# PIC32MM0128GPM064 register map
Vendor: Microchip
Registers are 32-bit, read-write, reset 0x0 unless marked. A register's access mark holds for its fields unless they carry their own. Addresses are absolute, and some are shared; only a register's first bit layout is shown; [hi:lo] are bit positions; {n}, {i} and the like mark numbered series.

## INT
0x1F802A00 RPCON
  [11] IOLOCK
0x1F802A20 RPINR1
  [4:0] INT4R
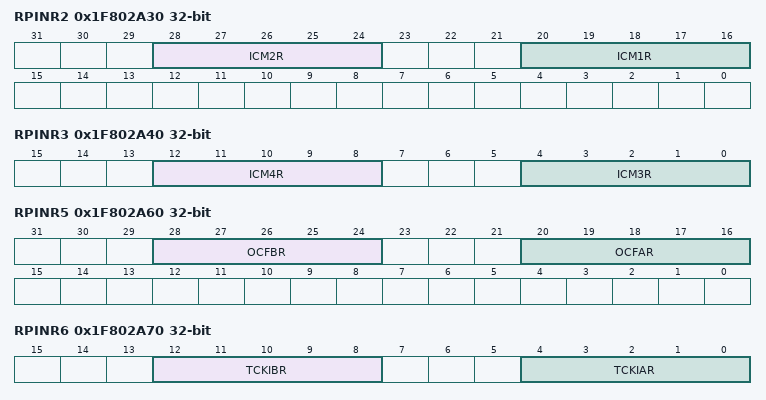
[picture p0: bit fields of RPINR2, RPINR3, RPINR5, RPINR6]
0x1F802A30 RPINR2
  [28:24] ICM2R, [20:16] ICM1R
0x1F802A40 RPINR3
  [12:8] ICM4R, [4:0] ICM3R
0x1F802A60 RPINR5
  [28:24] OCFBR, [20:16] OCFAR
0x1F802A70 RPINR6
  [12:8] TCKIBR, [4:0] TCKIAR
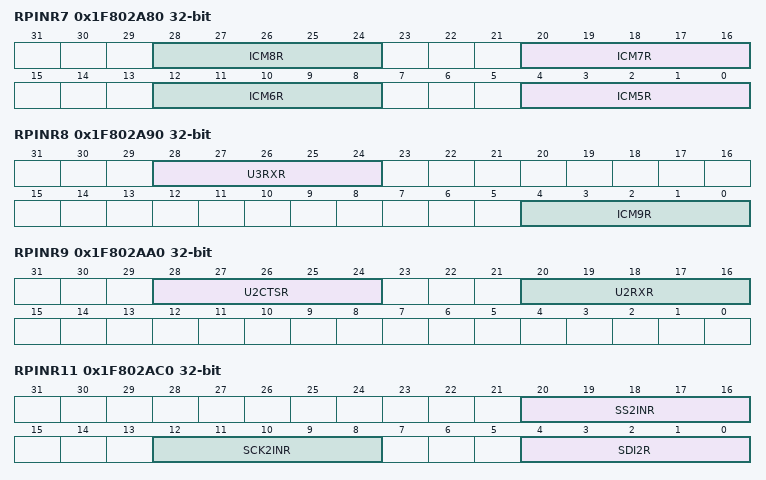
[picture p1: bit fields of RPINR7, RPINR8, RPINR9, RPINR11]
0x1F802A80 RPINR7
  [8n-36:8n-40] ICM{n}R (n=5..8)
0x1F802A90 RPINR8
  [28:24] U3RXR, [4:0] ICM9R
0x1F802AA0 RPINR9
  [28:24] U2CTSR, [20:16] U2RXR
0x1F802AB0 RPINR10
  [28:24] U3CTSR
0x1F802AC0 RPINR11
  [20:16] SS2INR, [12:8] SCK2INR, [4:0] SDI2R
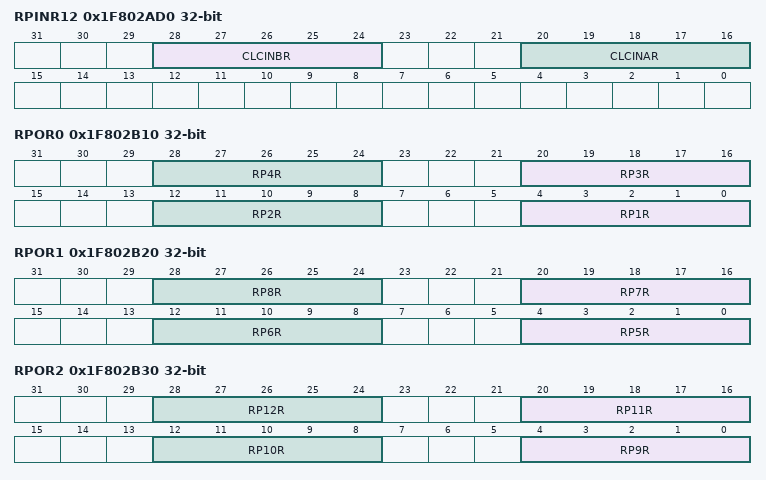
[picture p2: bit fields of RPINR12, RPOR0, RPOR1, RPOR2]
0x1F802AD0 RPINR12
  [28:24] CLCINBR, [20:16] CLCINAR
0x1F802B10 RPOR0
  [8n-4:8n-8] RP{n}R (n=1..4)
0x1F802B20 RPOR1
  [8n-36:8n-40] RP{n}R (n=5..8)
0x1F802B30 RPOR2
  [8n-68:8n-72] RP{n}R (n=9..12)
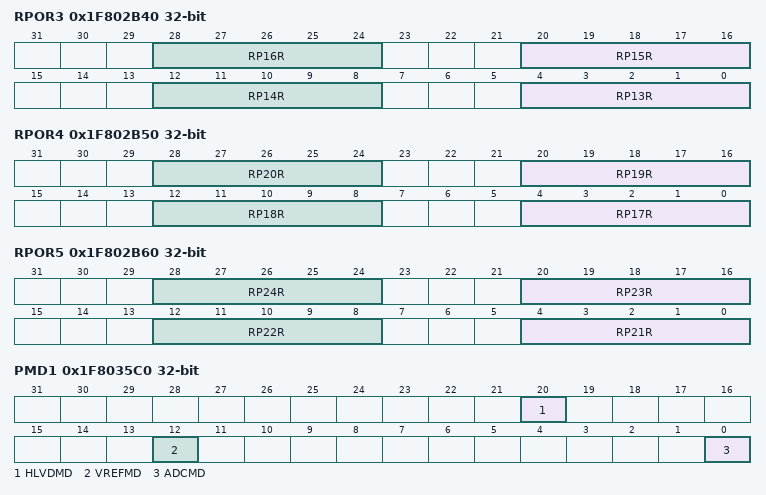
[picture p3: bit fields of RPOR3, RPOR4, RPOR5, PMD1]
0x1F802B40 RPOR3
  [8n-100:8n-104] RP{n}R (n=13..16)
0x1F802B50 RPOR4
  [8n-132:8n-136] RP{n}R (n=17..20)
0x1F802B60 RPOR5 reset not defined — (power-on value ---xxxxx---xxxxx---xxxxx---xxxxx)
  [8n-164:8n-168] RP{n}R (n=21..24)
0x1F8035B0 PMDCON
  [11] PMDLOCK
0x1F8035C0 PMD1
  [20] HLVDMD, [12] VREFMD, [0] ADCMD
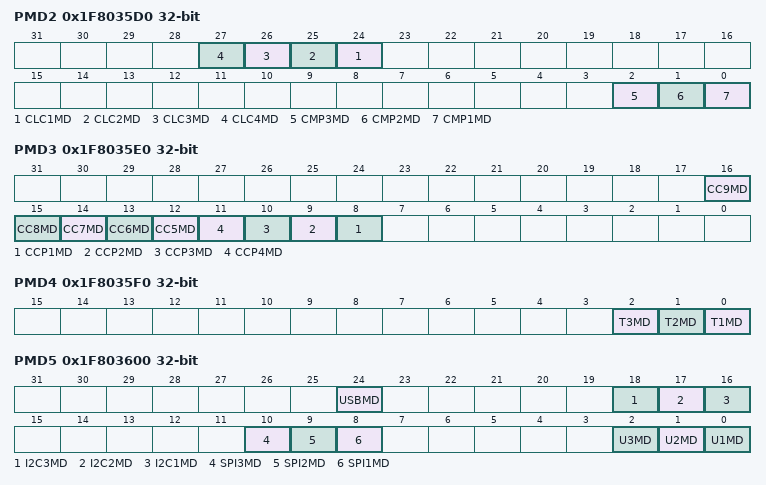
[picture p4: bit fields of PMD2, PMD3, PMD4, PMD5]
0x1F8035D0 PMD2
  [n+23] CLC{n}MD (n=1..4), [2] CMP3MD, [1] CMP2MD, [0] CMP1MD
0x1F8035E0 PMD3
  [n+7] CC{n}MD (n=5..9), [n+7] CCP{n}MD (n=1..4)
0x1F8035F0 PMD4
  [2] T3MD, [1] T2MD, [0] T1MD
0x1F803600 PMD5
  [24] USBMD, [18] I2C3MD, [17] I2C2MD, [16] I2C1MD, [10] SPI3MD, [9] SPI2MD, [8] SPI1MD, [2] U3MD, [1] U2MD, [0] U1MD
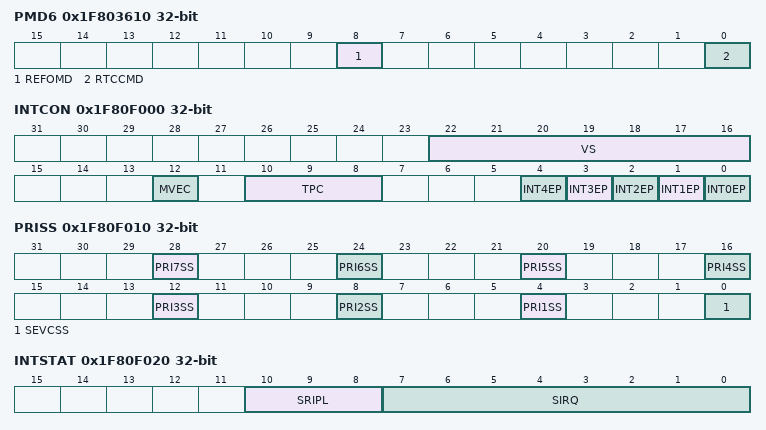
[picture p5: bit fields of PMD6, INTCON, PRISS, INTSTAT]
0x1F803610 PMD6
  [8] REFOMD, [0] RTCCMD
0x1F803620 PMD7
  [4] DMAMD
0x1F80F000 INTCON reset not defined — (power-on value ---------0000000-x-0-000---00000)
  [22:16] VS, [12] MVEC, [10:8] TPC, [n] INT{n}EP (n=0..4)
0x1F80F010 PRISS reset not defined — (power-on value ---x---x---x---x---x---x---x---x)
  [4n] PRI{n}SS (n=1..7), [0] SEVCSS
0x1F80F020 INTSTAT ro
  [10:8] SRIPL, [7:0] SIRQ
0x1F80F030 IPTMR
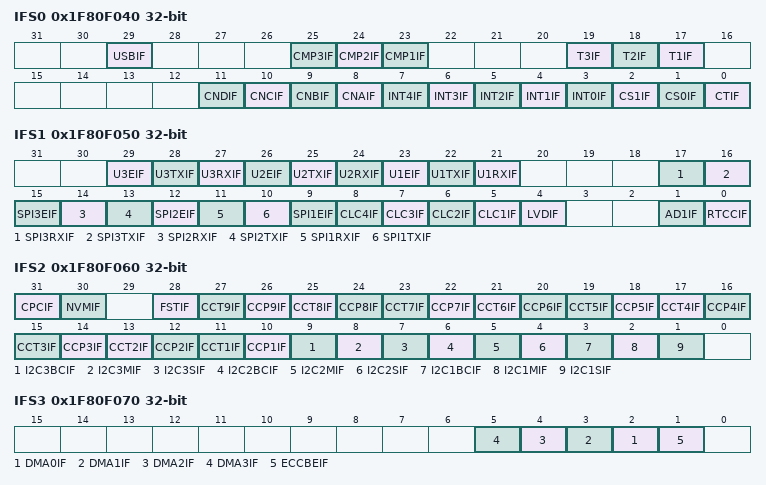
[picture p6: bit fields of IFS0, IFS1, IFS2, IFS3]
0x1F80F040 IFS0
  [29] USBIF, [25] CMP3IF, [24] CMP2IF, [23] CMP1IF, [19] T3IF, [18] T2IF, [17] T1IF, [11] CNDIF, [10] CNCIF, [9] CNBIF, [8] CNAIF, [n+3] INT{n}IF (n=0..4), [2] CS1IF, [1] CS0IF, [0] CTIF
0x1F80F050 IFS1
  [29] U3EIF, [28] U3TXIF, [27] U3RXIF, [26] U2EIF, [25] U2TXIF, [24] U2RXIF, [23] U1EIF, [22] U1TXIF, [21] U1RXIF, [17] SPI3RXIF, [16] SPI3TXIF, [15] SPI3EIF, [14] SPI2RXIF, [13] SPI2TXIF, [12] SPI2EIF, [11] SPI1RXIF, [10] SPI1TXIF, [9] SPI1EIF, [n+4] CLC{n}IF (n=1..4), [4] LVDIF, [1] AD1IF, [0] RTCCIF
0x1F80F060 IFS2 reset not defined — (power-on value 0x-00000000000000000000000000000)
  [31] CPCIF, [30] NVMIF, [28] FSTIF, [2n+9] CCT{n}IF (n=1..9), [2n+8] CCP{n}IF (n=1..9), [9] I2C3BCIF, [8] I2C3MIF, [7] I2C3SIF, [6] I2C2BCIF, [5] I2C2MIF, [4] I2C2SIF, [3] I2C1BCIF, [2] I2C1MIF, [1] I2C1SIF
0x1F80F070 IFS3 reset not defined — (power-on value 000000000000000000000000--x0000-)
  [n+2] DMA{n}IF (n=0..3), [1] ECCBEIF
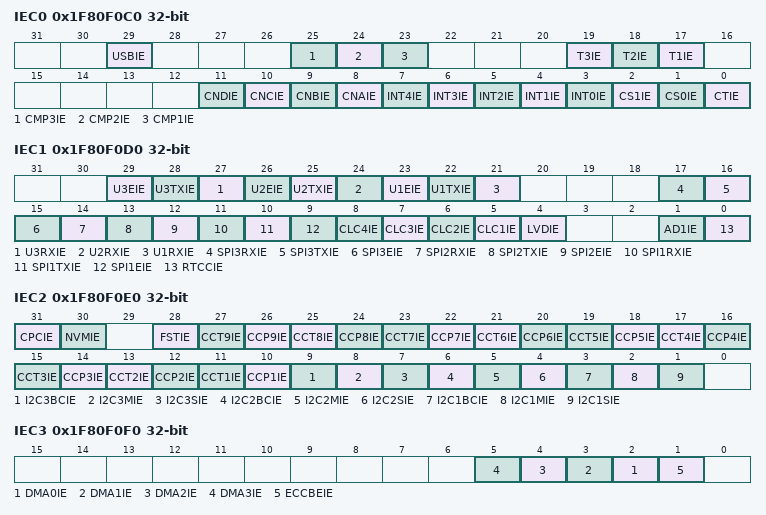
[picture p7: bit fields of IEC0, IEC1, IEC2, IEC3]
0x1F80F0C0 IEC0 reset not defined — (power-on value --x---000---000-----000000000000)
  [29] USBIE, [25] CMP3IE, [24] CMP2IE, [23] CMP1IE, [19] T3IE, [18] T2IE, [17] T1IE, [11] CNDIE, [10] CNCIE, [9] CNBIE, [8] CNAIE, [n+3] INT{n}IE (n=0..4), [2] CS1IE, [1] CS0IE, [0] CTIE
0x1F80F0D0 IEC1
  [29] U3EIE, [28] U3TXIE, [27] U3RXIE, [26] U2EIE, [25] U2TXIE, [24] U2RXIE, [23] U1EIE, [22] U1TXIE, [21] U1RXIE, [17] SPI3RXIE, [16] SPI3TXIE, [15] SPI3EIE, [14] SPI2RXIE, [13] SPI2TXIE, [12] SPI2EIE, [11] SPI1RXIE, [10] SPI1TXIE, [9] SPI1EIE, [n+4] CLC{n}IE (n=1..4), [4] LVDIE, [1] AD1IE, [0] RTCCIE
0x1F80F0E0 IEC2 reset not defined — (power-on value 0x-00000000000000000000000000000)
  [31] CPCIE, [30] NVMIE, [28] FSTIE, [2n+9] CCT{n}IE (n=1..9), [2n+8] CCP{n}IE (n=1..9), [9] I2C3BCIE, [8] I2C3MIE, [7] I2C3SIE, [6] I2C2BCIE, [5] I2C2MIE, [4] I2C2SIE, [3] I2C1BCIE, [2] I2C1MIE, [1] I2C1SIE
0x1F80F0F0 IEC3
  [n+2] DMA{n}IE (n=0..3), [1] ECCBEIE
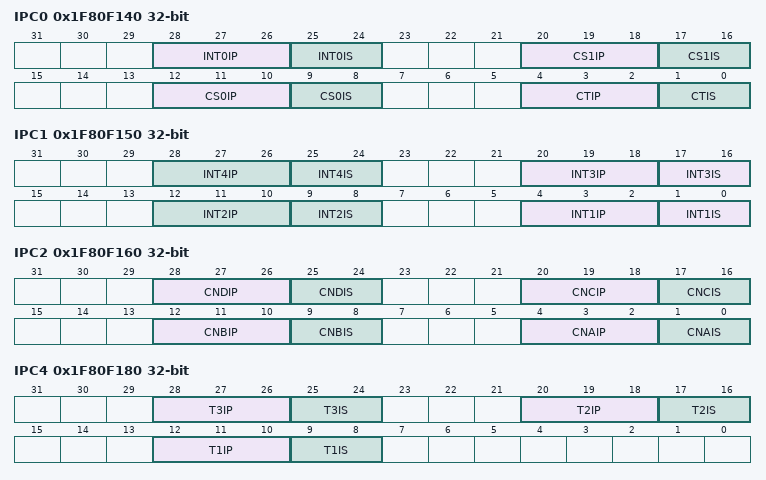
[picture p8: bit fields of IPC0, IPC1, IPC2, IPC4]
0x1F80F140 IPC0
  [28:26] INT0IP, [25:24] INT0IS, [20:18] CS1IP, [17:16] CS1IS, [12:10] CS0IP, [9:8] CS0IS, [4:2] CTIP, [1:0] CTIS
0x1F80F150 IPC1
  [8n-4:8n-6] INT{n}IP (n=1..4), [8n-7:8n-8] INT{n}IS (n=1..4)
0x1F80F160 IPC2
  [28:26] CNDIP, [25:24] CNDIS, [20:18] CNCIP, [17:16] CNCIS, [12:10] CNBIP, [9:8] CNBIS, [4:2] CNAIP, [1:0] CNAIS
0x1F80F170 IPC3 access not given reset not defined
0x1F80F180 IPC4
  [28:26] T3IP, [25:24] T3IS, [20:18] T2IP, [17:16] T2IS, [12:10] T1IP, [9:8] T1IS
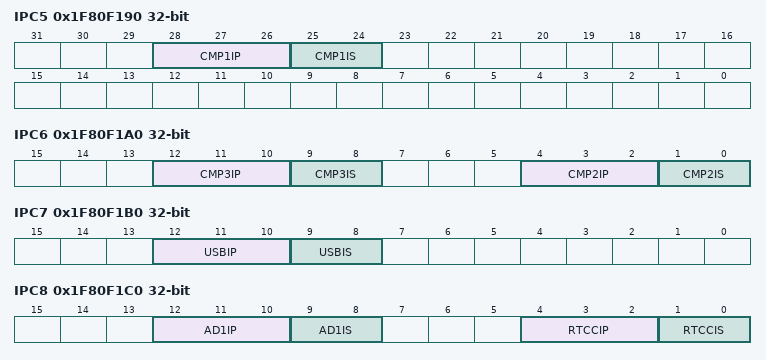
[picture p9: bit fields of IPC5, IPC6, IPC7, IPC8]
0x1F80F190 IPC5
  [28:26] CMP1IP, [25:24] CMP1IS
0x1F80F1A0 IPC6
  [12:10] CMP3IP, [9:8] CMP3IS, [4:2] CMP2IP, [1:0] CMP2IS
0x1F80F1B0 IPC7
  [12:10] USBIP, [9:8] USBIS
0x1F80F1C0 IPC8
  [12:10] AD1IP, [9:8] AD1IS, [4:2] RTCCIP, [1:0] RTCCIS
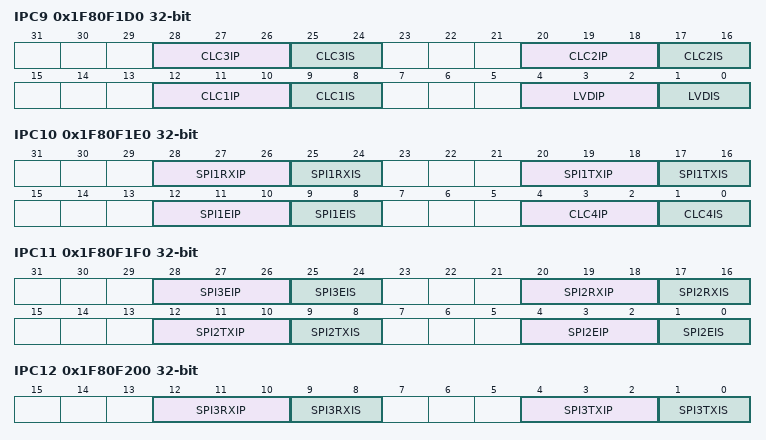
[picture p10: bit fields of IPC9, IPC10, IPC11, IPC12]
0x1F80F1D0 IPC9 reset not defined — (power-on value ---00000---00000---00000---xxxxx)
  [28:26] CLC3IP, [25:24] CLC3IS, [20:18] CLC2IP, [17:16] CLC2IS, [12:10] CLC1IP, [9:8] CLC1IS, [4:2] LVDIP, [1:0] LVDIS
0x1F80F1E0 IPC10
  [28:26] SPI1RXIP, [25:24] SPI1RXIS, [20:18] SPI1TXIP, [17:16] SPI1TXIS, [12:10] SPI1EIP, [9:8] SPI1EIS, [4:2] CLC4IP, [1:0] CLC4IS
0x1F80F1F0 IPC11
  [28:26] SPI3EIP, [25:24] SPI3EIS, [20:18] SPI2RXIP, [17:16] SPI2RXIS, [12:10] SPI2TXIP, [9:8] SPI2TXIS, [4:2] SPI2EIP, [1:0] SPI2EIS
0x1F80F200 IPC12 reset not defined — (power-on value -------------------00000---xxxxx)
  [12:10] SPI3RXIP, [9:8] SPI3RXIS, [4:2] SPI3TXIP, [1:0] SPI3TXIS
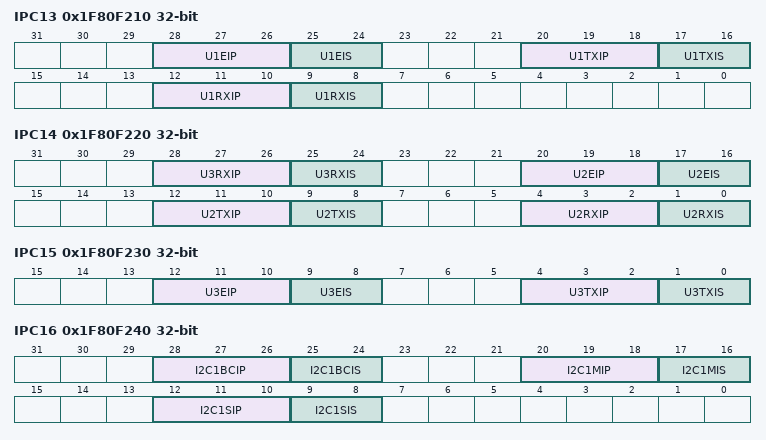
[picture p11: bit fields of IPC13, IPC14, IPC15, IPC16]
0x1F80F210 IPC13 reset not defined — (power-on value --0xxxxx00-xxxxx000xxxxx--------)
  [28:26] U1EIP, [25:24] U1EIS, [20:18] U1TXIP, [17:16] U1TXIS, [12:10] U1RXIP, [9:8] U1RXIS
0x1F80F220 IPC14 reset not defined — (power-on value 000xxxxx--0xxxxx00-xxxxx000xxxxx)
  [28:26] U3RXIP, [25:24] U3RXIS, [20:18] U2EIP, [17:16] U2EIS, [12:10] U2TXIP, [9:8] U2TXIS, [4:2] U2RXIP, [1:0] U2RXIS
0x1F80F230 IPC15 reset not defined — (power-on value -------------00000-xxxxx000xxxxx)
  [12:10] U3EIP, [9:8] U3EIS, [4:2] U3TXIP, [1:0] U3TXIS
0x1F80F240 IPC16 reset not defined — (power-on value --0xxxxx00-xxxxx000xxxxx--------)
  [28:26] I2C1BCIP, [25:24] I2C1BCIS, [20:18] I2C1MIP, [17:16] I2C1MIS, [12:10] I2C1SIP, [9:8] I2C1SIS
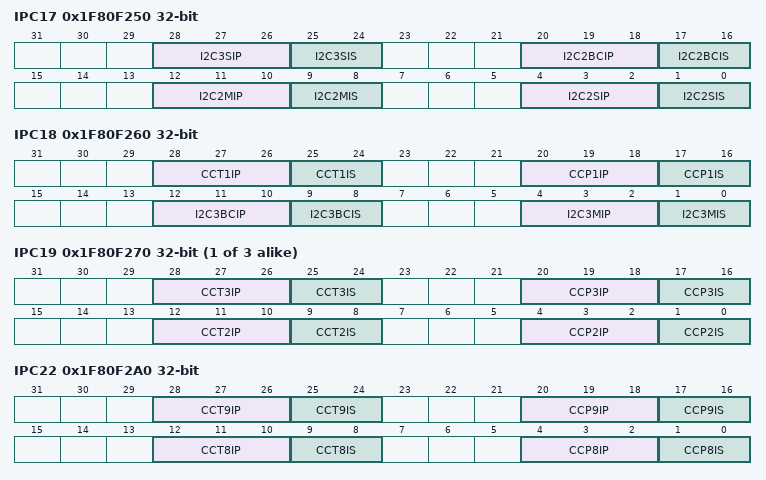
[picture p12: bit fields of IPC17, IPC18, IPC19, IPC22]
0x1F80F250 IPC17 reset not defined — (power-on value 000xxxxx--0xxxxx00-xxxxx000xxxxx)
  [28:26] I2C3SIP, [25:24] I2C3SIS, [20:18] I2C2BCIP, [17:16] I2C2BCIS, [12:10] I2C2MIP, [9:8] I2C2MIS, [4:2] I2C2SIP, [1:0] I2C2SIS
0x1F80F260 IPC18 reset not defined — (power-on value 000xxxxx--0xxxxx00-xxxxx000xxxxx)
  [28:26] CCT1IP, [25:24] CCT1IS, [20:18] CCP1IP, [17:16] CCP1IS, [12:10] I2C3BCIP, [9:8] I2C3BCIS, [4:2] I2C3MIP, [1:0] I2C3MIS
{0x1F80F140+0x10*i} IPC{i} reset not defined (i=19..21) — (power-on value 000xxxxx--0xxxxx00-xxxxx000xxxxx)
  [28:26] CCT{2i-35}IP, [25:24] CCT{2i-35}IS, [20:18] CCP{2i-35}IP, [17:16] CCP{2i-35}IS, [12:10] CCT{2i-36}IP, [9:8] CCT{2i-36}IS, [4:2] CCP{2i-36}IP, [1:0] CCP{2i-36}IS
0x1F80F2A0 IPC22 reset not defined — (power-on value 000xxxxx---xxxxx00-xxxxx000xxxxx)
  [28:26] CCT9IP, [25:24] CCT9IS, [20:18] CCP9IP, [17:16] CCP9IS, [12:10] CCT8IP, [9:8] CCT8IS, [4:2] CCP8IP, [1:0] CCP8IS
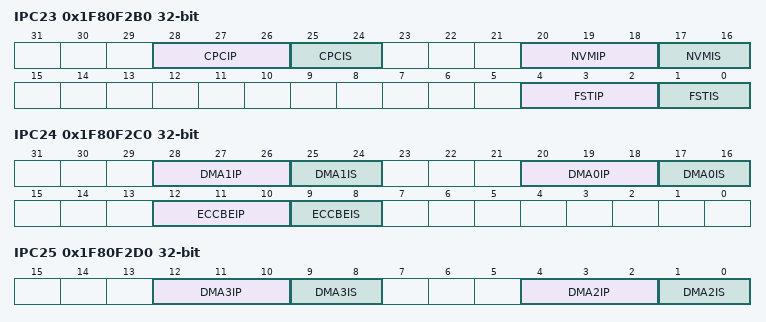
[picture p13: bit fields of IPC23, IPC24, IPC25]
0x1F80F2B0 IPC23 reset not defined — (power-on value 000xxxxx--0xxxxx00------000xxxxx)
  [28:26] CPCIP, [25:24] CPCIS, [20:18] NVMIP, [17:16] NVMIS, [4:2] FSTIP, [1:0] FSTIS
0x1F80F2C0 IPC24 reset not defined — (power-on value --0xxxxx00-xxxxx000xxxxx---00000)
  [28:26] DMA1IP, [25:24] DMA1IS, [20:18] DMA0IP, [17:16] DMA0IS, [12:10] ECCBEIP, [9:8] ECCBEIS
0x1F80F2D0 IPC25 reset not defined — (power-on value -------------00000-xxxxx000xxxxx)
  [12:10] DMA3IP, [9:8] DMA3IS, [4:2] DMA2IP, [1:0] DMA2IS
